# PIC32CX5109BZ36048_SL3 register map
Vendor: Microchip Technology; Series: PIC32CXBZ36; File version: 0
CPU: CM4 r0p1, little endian, MPU, FPU, 3 interrupt priority bits, 43 interrupts
Registers are 32-bit, read-write, reset 0x0 unless marked. A register's access mark holds for its fields unless they carry their own. Offsets are from the block's base; [hi:lo] are bit positions; {n}, {i} and the like mark numbered series; 'fields as' and 'values as' point back to an identical list.

## DWT — Data Watchpoint and Trace Register
Base 0xE0001000
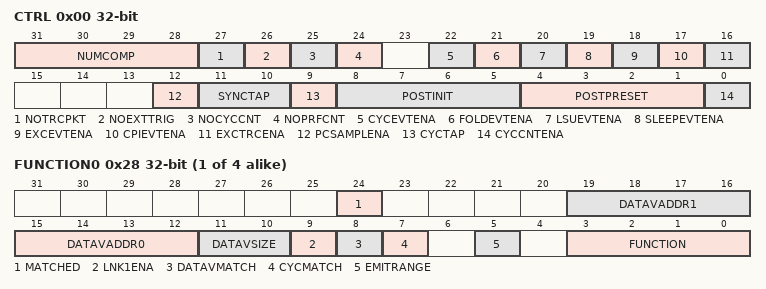
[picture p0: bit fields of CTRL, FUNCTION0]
0x00 CTRL — Control Register
  [31:28] NUMCOMP, [27] NOTRCPKT, [26] NOEXTTRIG, [25] NOCYCCNT, [24] NOPRFCNT, [22] CYCEVTENA, [21] FOLDEVTENA, [20] LSUEVTENA, [19] SLEEPEVTENA, [18] EXCEVTENA, [17] CPIEVTENA, [16] EXCTRCENA, [12] PCSAMPLENA, [11:10] SYNCTAP, [9] CYCTAP, [8:5] POSTINIT, [4:1] POSTPRESET, [0] CYCCNTENA
0x04 CYCCNT — Cycle Count Register
0x08 CPICNT — CPI Count Register
  [7:0] CPICNT
0x0C EXCCNT — Exception Overhead Count Register
  [7:0] EXCCNT
0x10 SLEEPCNT — Sleep Count Register
  [7:0] SLEEPCNT
0x14 LSUCNT — LSU Count Register
  [7:0] LSUCNT
0x18 FOLDCNT — Folded-instruction Count Register
  [7:0] FOLDCNT
0x1C PCSR ro — Program Counter Sample Register
{0x20+0x10*i} COMP{i} (i=0..3) — Comparator Register {i}
{0x24+0x10*i} MASK{i} (i=0..3) — Mask Register {i}
  [4:0] MASK
{0x28+0x10*i} FUNCTION{i} (i=0..3) — Function Register {i}
  [24] MATCHED, [19:16] DATAVADDR1, [15:12] DATAVADDR0, [11:10] DATAVSIZE, [9] LNK1ENA, [8] DATAVMATCH, [7] CYCMATCH, [5] EMITRANGE, [3:0] FUNCTION

## EIC — External Interrupt Controller
Base 0x40000800
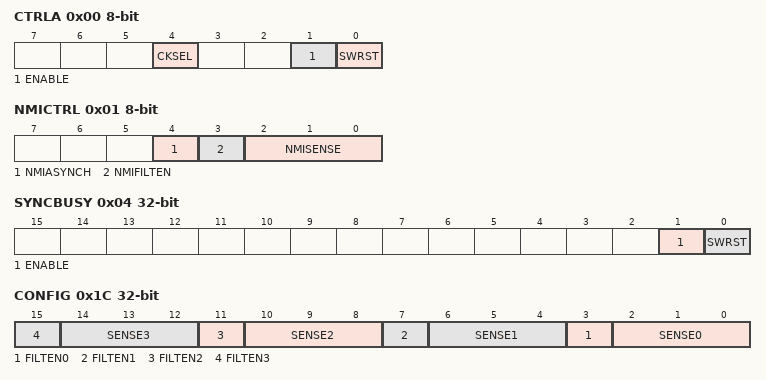
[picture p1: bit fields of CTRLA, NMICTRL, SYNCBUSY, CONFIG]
0x00 CTRLA 8-bit — Control A
  [4] CKSEL — Clock Selection
    0=CLK_GCLK (Clocked by GCLK); 1=32KHZ_LPCLK (Clocked by LPCLK)
  [1] ENABLE
  [0] SWRST — Software Reset
0x01 NMICTRL 8-bit — Non-Maskable Interrupt Control
  [4] NMIASYNCH — Asynchronous Edge Detection Mode
    0=SYNC (Edge detection is clock synchronously operated); 1=ASYNC (Edge detection is clock asynchronously operated)
  [3] NMIFILTEN — Non-Maskable Interrupt Filter Enable
  [2:0] NMISENSE — Non-Maskable Interrupt Sense Configuration
    0=NONE (No detection); 1=RISE (Rising-edge detection); 2=FALL (Falling-edge detection); 3=BOTH (Both-edges detection); 4=HIGH (High-level detection); 5=LOW (Low-level detection)
0x02 NMIFLAG 16-bit write-1-clears — Non-Maskable Interrupt Flag Status and Clear
  [0] NMI — Non-Maskable Interrupt
0x04 SYNCBUSY ro — Synchronization Busy
  [1] ENABLE — Enable Synchronization Busy Status
  [0] SWRST — Software Reset Synchronization Busy Status
0x08 EVCTRL — Event Control
  [3:0] EXTINTEO — External Interrupt Event Output Enable
0x0C INTENCLR write-1-clears — Interrupt Enable Clear
  [3:0] EXTINT — External Interrupt Enable
0x10 INTENSET write-1-sets — Interrupt Enable Set
  [3:0] EXTINT — External Interrupt Enable
0x14 INTFLAG write-1-clears — Interrupt Flag Status and Clear
  [3:0] EXTINT — External Interrupt
0x18 ASYNCH — External Interrupt Asynchronous Mode
  [3:0] ASYNCH — Asynchronous Edge Detection Mode
    values as NMICTRL.NMIASYNCH
0x1C CONFIG — External Interrupt Sense Configuration
  [4n+3] FILTEN{n} (n=0..3) — Filter Enable {n}
  [4n+2:4n] SENSE{n} (n=0..3) — Input Sense Configuration {n}
    0=NONE (No detection); 1=RISE (Rising edge detection); 2=FALL (Falling edge detection); 3=BOTH (Both edges detection); 4=HIGH (High level detection); 5=LOW (Low level detection)
0x30 DEBOUNCEN — Debouncer Enable
  [3:0] DEBOUNCEN
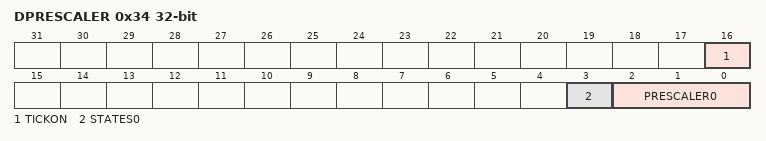
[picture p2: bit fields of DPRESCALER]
0x34 DPRESCALER — Debouncer Prescaler
  [16] TICKON — Pin Sampler frequency selection
    0=CLK_GCLK_EIC (Clocked by GCLK); 1=CLK_LFREQ (Clocked by Low Frequency Clock)
  [3] STATES0 — Debouncer number of states
    0=LFREQ3 (3 low frequency samples); 1=LFREQ7 (7 low frequency samples)
  [2:0] PRESCALER0 — Debouncer Prescaler
    0=DIV2 (EIC clock divided by 2); 1=DIV4 (EIC clock divided by 4); 2=DIV8 (EIC clock divided by 8); 3=DIV16 (EIC clock divided by 16); 4=DIV32 (EIC clock divided by 32); 5=DIV64 (EIC clock divided by 64); 6=DIV128 (EIC clock divided by 128); 7=DIV256 (EIC clock divided by 256)
0x38 PINSTATE ro
  [3:0] PINSTATE
